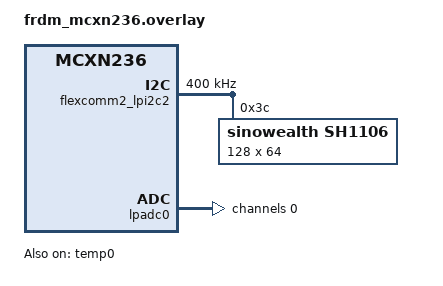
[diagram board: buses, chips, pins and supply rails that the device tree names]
/* frdm_mcxn236.overlay */
#include <zephyr/dt-bindings/adc/adc.h>
#include <zephyr/dt-bindings/adc/mcux-lpadc.h>


/ {
	aliases {
		die-temp0 = &temp0;
	};
};

&flexcomm2_lpi2c2 {
  status = "okay";

  clock-frequency = <I2C_BITRATE_FAST>;

  sh1106: sh1106@3c {
    compatible = "sinowealth,sh1106";
    reg = <0x3c>;
    width = <128>;
    height = <64>;
    segment-offset = <2>;
    display-offset = <0>;
    page-offset = <0>;
    multiplex-ratio = <63>;
    segment-remap;
    com-invdir;
    prechargep = <0x22>;
  };
};

&lpadc0 {
	status = "okay";
	#address-cells = <1>;
	#size-cells = <0>;

	channel@0 {
		reg = <0>;
		
		/* Restored required gain property */
		zephyr,gain = "ADC_GAIN_1";
		
		zephyr,vref-mv = <3300>; 
		zephyr,reference = "ADC_REF_EXTERNAL0";
		zephyr,acquisition-time = <ADC_ACQ_TIME(ADC_ACQ_TIME_TICKS, 131)>;
		zephyr,oversampling = <4>; 
		zephyr,input-positive = <MCUX_LPADC_CH26A>;
		zephyr,resolution = <16>;
	};
};

&temp0 {
	status = "okay";
	io-channels = <&lpadc0 0>;
};
